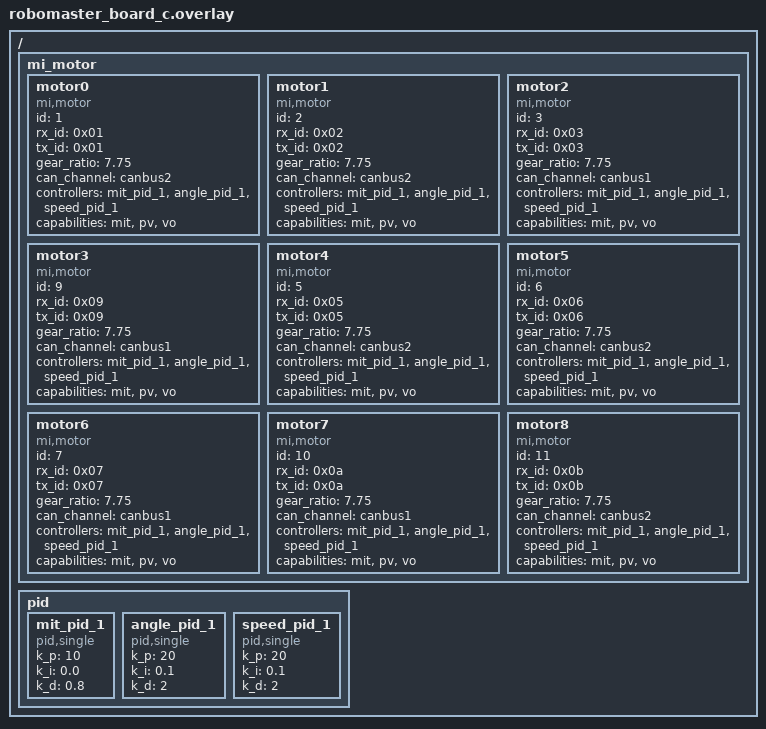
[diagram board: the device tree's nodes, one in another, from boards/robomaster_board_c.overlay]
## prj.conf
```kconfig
#启用线程分析器
# CONFIG_THREAD_ANALYZER=y
# CONFIG_THREAD_ANALYZER_USE_LOG=y
# CONFIG_THREAD_ANALYZER_USE_PRINTK=n
# CONFIG_THREAD_NAME=y
# CONFIG_THREAD_ANALYZER_AUTO=y
# CONFIG_THREAD_ANALYZER_AUTO_INTERVAL=5
# CONFIG_THREAD_ANALYZER_LOG_LEVEL_INF=y
# CONFIG_THREAD_ANALYZER_AUTO_SEPARATE_CORES=n

# 启用 UART 控制台
CONFIG_UART_CONSOLE=y

# 禁用 SEGGER RTT
CONFIG_USE_SEGGER_RTT=n

# 启用事件支持
CONFIG_EVENTS=y

# 启用串行支持
CONFIG_SERIAL=y
CONFIG_SPI_ASYNC=y
# 禁用优化
CONFIG_NO_OPTIMIZATIONS=y

# 启用驱动
CONFIG_MOTOR=y
# CONFIG_MOTOR_DJI=y
CONFIG_MOTOR_MI=y
CONFIG_MOTOR_LOG_LEVEL=4
CONFIG_CAN=y
CONFIG_MOTOR_INIT_PRIORITY=90
CONFIG_PID=y

CONFIG_ARES=y
CONFIG_ARES_SBUS=y
CONFIG_SBUS_INIT_PRIORITY=90

CONFIG_DMA=y
CONFIG_DMA_STM32=y  # STM32 DMA 驱动
CONFIG_UART_STM32=y # STM32 UART 驱动
# CONFIG_STM32_UART_DMA=y


# CONFIG_HAS_STM32CUBE=y
# CONFIG_USE_STM32_HAL_DMA=y
# CONFIG_SPI=y
# CONFIG_SPI_STM32=y

#
# Device Drivers
#
# CONFIG_SENSOR=y
# CONFIG_BMI08X=y
# CONFIG_BMI08X_ACCEL_TRIGGER_NONE is not set
# CONFIG_BMI08X_ACCEL_TRIGGER_GLOBAL_THREAD=y
# CONFIG_BMI08X_ACCEL_TRIGGER_OWN_THREAD is not set
# CONFIG_BMI08X_GYRO_TRIGGER_NONE is not set
# CONFIG_BMI08X_GYRO_TRIGGER_GLOBAL_THREAD=y
# CONFIG_BMI08X_GYRO_TRIGGER_OWN_THREAD is not set
# CONFIG_BMI08X_I2C_WRITE_BURST_SIZE=16

CONFIG_DEBUG_THREAD_INFO=y
CONFIG_MAIN_STACK_SIZE=4096
```

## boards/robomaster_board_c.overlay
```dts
/ {
	mi_motor {
		motor0: motor0{
			compatible = "mi,motor";
            
			id = <1>;
            rx_id = <0x01>;
            tx_id = <0x01>;
			gear_ratio = "7.75";
			status = "okay";
			can_channel = <&canbus2>;
			controllers = <&mit_pid_1 &angle_pid_1 &speed_pid_1>;
			capabilities = "mit","pv", "vo";
		};

		motor1: motor1{
			compatible = "mi,motor";
            
			id = <2>;
            rx_id = <0x02>;
            tx_id = <0x02>;
			gear_ratio = "7.75";
			status = "okay";
			can_channel = <&canbus2>;
			controllers = <&mit_pid_1 &angle_pid_1 &speed_pid_1>;
			capabilities = "mit","pv", "vo";
		};

		motor2: motor2{
			compatible = "mi,motor";
            
			id = <3>;
            rx_id = <0x03>;
            tx_id = <0x03>;
			gear_ratio = "7.75";
			status = "okay";
			can_channel = <&canbus1>;
			controllers = <&mit_pid_1 &angle_pid_1 &speed_pid_1>;
			capabilities = "mit","pv", "vo";
		};

		motor3: motor3{
			compatible = "mi,motor";
            
			id = <9>;
            rx_id = <0x09>;
            tx_id = <0x09>;
			gear_ratio = "7.75";
			status = "okay";
			can_channel = <&canbus1>;
			controllers = <&mit_pid_1 &angle_pid_1 &speed_pid_1>;
			capabilities = "mit","pv", "vo";
		};
		
		motor4: motor4{
			compatible = "mi,motor";
            
			id = <5>;
            rx_id = <0x05>;
            tx_id = <0x05>;
			gear_ratio = "7.75";
			status = "okay";
			can_channel = <&canbus2>;
			controllers = <&mit_pid_1 &angle_pid_1 &speed_pid_1>;
			capabilities = "mit","pv", "vo";
		};

		motor5: motor5{
			compatible = "mi,motor";
            
			id = <6>;
            rx_id = <0x06>;
            tx_id = <0x06>;
			gear_ratio = "7.75";
			status = "okay";
			can_channel = <&canbus2>;
			controllers = <&mit_pid_1 &angle_pid_1 &speed_pid_1>;
			capabilities = "mit","pv", "vo";
		};

		motor6: motor6{
			compatible = "mi,motor";
            
			id = <7>;
            rx_id = <0x07>;
            tx_id = <0x07>;
			gear_ratio = "7.75";
			status = "okay";
			can_channel = <&canbus1>;
			controllers = <&mit_pid_1 &angle_pid_1 &speed_pid_1>;
			capabilities = "mit","pv", "vo";
		};

		motor7: motor7{
			compatible = "mi,motor";
            
			id = <10>;
            rx_id = <0x0a>;
            tx_id = <0x0a>;
			gear_ratio = "7.75";
			status = "okay";
			can_channel = <&canbus1>;
			controllers = <&mit_pid_1 &angle_pid_1 &speed_pid_1>;
			capabilities = "mit","pv", "vo";
		};
		motor8: motor8{
			compatible = "mi,motor";
            
			id = <11>;
            rx_id = <0x0b>;
            tx_id = <0x0b>;
			gear_ratio = "7.75";
			status = "okay";
			can_channel = <&canbus2>;
			controllers = <&mit_pid_1 &angle_pid_1 &speed_pid_1>;
			capabilities = "mit","pv", "vo";
		};
	};

	pid {
		mit_pid_1: mit_pid_1 {
			#controller-cells = <0>;
			compatible = "pid,single";
			k_p = "10";
			k_i = "0.0";
			k_d = "0.8";
		};
		angle_pid_1: angle_pid_1 {
			#controller-cells = <0>;
			compatible = "pid,single";
			k_p = "20";
			k_i = "0.1";
			k_d = "2";
		};
		speed_pid_1: speed_pid_1 {
			#controller-cells = <0>;
			compatible = "pid,single";
			k_p = "20";
			k_i = "0.1";
			k_d = "2";
		};
		
	};
	
};
```

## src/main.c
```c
#include "ares/board/init.h"
#include "math.h"
#include <stddef.h>
#include <stdint.h>
#include <stdio.h>
#include <zephyr/debug/thread_analyzer.h>
#include <zephyr/device.h>
#include <zephyr/devicetree.h>
#include <zephyr/drivers/can.h>
#include <zephyr/drivers/motor.h>
#include <zephyr/drivers/sbus.h>
#include <zephyr/drivers/sensor.h>
#include <zephyr/drivers/uart.h>
#include <zephyr/kernel.h>
#include <zephyr/logging/log.h>
#include <zephyr/sys/printk.h>
#include "cycloid.h"

LOG_MODULE_REGISTER(main, LOG_LEVEL_DBG);

#define G 9.80665f

#define HIGH_BYTE(x) ((x) >> 8)
#define LOW_BYTE(x) ((x)&0xFF)
#define COMBINE_HL8(HIGH, LOW) ((HIGH << 8) + LOW)

#define MOTOR1_NODE DT_INST(0, mi_motor)
#define MOTOR2_NODE DT_INST(1, mi_motor)
#define MOTOR3_NODE DT_INST(2, mi_motor)
#define MOTOR4_NODE DT_INST(3, mi_motor)
#define MOTOR5_NODE DT_INST(4, mi_motor)
#define MOTOR6_NODE DT_INST(5, mi_motor)
#define MOTOR7_NODE DT_INST(6, mi_motor)
#define MOTOR8_NODE DT_INST(7, mi_motor)
#define MOTOR9_NODE DT_INST(8, mi_motor)

const struct device *motor1 = DEVICE_DT_GET(MOTOR1_NODE);
const struct device *motor2 = DEVICE_DT_GET(MOTOR2_NODE);
const struct device *motor3 = DEVICE_DT_GET(MOTOR3_NODE);
const struct device *motor4 = DEVICE_DT_GET(MOTOR4_NODE);
const struct device *motor5 = DEVICE_DT_GET(MOTOR5_NODE);
const struct device *motor6 = DEVICE_DT_GET(MOTOR6_NODE);
const struct device *motor7 = DEVICE_DT_GET(MOTOR7_NODE);
const struct device *motor8 = DEVICE_DT_GET(MOTOR8_NODE);
const struct device *motor9 = DEVICE_DT_GET(MOTOR8_NODE);

// #define TIMER_NODE DT_NODELABEL(timers10)
// const struct device *timer = DEVICE_DT_GET(TIMER_NODE);
k_tid_t feedback_tid = 0;
k_tid_t leg1_tid = 0;
k_tid_t leg2_tid = 0;
k_tid_t leg3_tid = 0;
k_tid_t leg4_tid = 0;
k_tid_t waist_tid = 0;

/* CAN Feedback to console*/
K_THREAD_STACK_DEFINE(feedback_stack_area, 4096); // 定义线程栈
void console_feedback(void *arg1, void *arg2, void *arg3) {

  while (1) {
    // LOG_INF("rpm: motor1: %.2f %.2f\n", (double)motor1_rpm,
    //         (double)motor_get_speed(motor1));
    // LOG_INF("rpm: motor2: %.2f %.2f\n", (double)motor2_rpm,
    //         (double)motor_get_speed(motor2));
    k_msleep(200);
  }
}

K_THREAD_STACK_DEFINE(leg1_stack, STACK_SIZE);
K_THREAD_STACK_DEFINE(leg2_stack, STACK_SIZE);
K_THREAD_STACK_DEFINE(leg3_stack, STACK_SIZE);
K_THREAD_STACK_DEFINE(leg4_stack, STACK_SIZE);
K_THREAD_STACK_DEFINE(waist_stack, STACK_SIZE);

float forward_angle1[TRAJ_POINTS];
float forward_angle4[TRAJ_POINTS];
float backward_angle1[TRAJ_POINTS];
float backward_angle4[TRAJ_POINTS];

int main(void) 
{
  Point2D start = {-0.15f, -0.20f};
  Point2D end = {0.15f, -0.2f};

  leg_motors leg1 = { motor1, motor2, LEFT_BACK};
  leg_motors leg2 = { motor4, motor3, RIGHT_BACK};
  leg_motors leg3 = { motor5, motor6, LEFT_FRONT};
  leg_motors leg4 = { motor8, motor7, RIGHT_FRONT};
  
  dog_initialization(start,end,forward_angle1,forward_angle4,backward_angle1,backward_angle4);
  k_sleep(K_MSEC(500)); 
  // motor_control(motor1, ENABLE_MOTOR); k_sleep(K_MSEC(10));
  // motor_control(motor2, ENABLE_MOTOR); k_sleep(K_MSEC(10));
  // motor_control(motor3, ENABLE_MOTOR); k_sleep(K_MSEC(10));
  // motor_control(motor4, ENABLE_MOTOR); k_sleep(K_MSEC(10));
  // motor_control(motor5, ENABLE_MOTOR); k_sleep(K_MSEC(10));
  // motor_control(motor6, ENABLE_MOTOR); k_sleep(K_MSEC(10));
  // motor_control(motor7, ENABLE_MOTOR); k_sleep(K_MSEC(10));
  // motor_control(motor8, ENABLE_MOTOR); k_sleep(K_MSEC(10));
  
  motor_set_mode(motor1, MIT);  k_sleep(K_MSEC(1));
  motor_set_mode(motor2, MIT);  k_sleep(K_MSEC(1));
  motor_set_mode(motor3, MIT);  k_sleep(K_MSEC(1));
  motor_set_mode(motor4, MIT);  k_sleep(K_MSEC(10));
  motor_set_mode(motor5, MIT);  k_sleep(K_MSEC(1));
  motor_set_mode(motor6, MIT);  k_sleep(K_MSEC(1));
  motor_set_mode(motor7, MIT);  k_sleep(K_MSEC(10));
  motor_set_mode(motor8, MIT);  k_sleep(K_MSEC(10));

  // Leg leg1 = { motor1, motor2, INITIAL_ANGLE1, INITIAL_ANGLE2, LEFT_BACK};
  // Leg leg2 = { motor4, motor3, INITIAL_ANGLE3, INITIAL_ANGLE4, RIGHT_BACK};
  // Leg leg3 = { motor5, motor6, INITIAL_ANGLE5, INITIAL_ANGLE6, LEFT_FRONT};
  // Leg leg4 = { motor8, motor7, INITIAL_ANGLE7, INITIAL_ANGLE8, RIGHT_FRONT};

  /* Start Feedback thread*/
  struct k_thread feedback_thread_data;
  struct k_thread leg1_thread_data;
  struct k_thread leg2_thread_data;
  struct k_thread leg3_thread_data;
  struct k_thread leg4_thread_data;
  struct k_thread waist_thread_data;

  k_sleep(K_MSEC(500));

  feedback_tid = k_thread_create(
      &feedback_thread_data,
      feedback_stack_area, // 修改为 can_send_stack_area
      K_THREAD_STACK_SIZEOF(feedback_stack_area), console_feedback,
      (void *)motor1, NULL, NULL, 0, 0, K_MSEC(300));

  leg1_tid = k_thread_create(&leg1_thread_data, leg1_stack, K_THREAD_STACK_SIZEOF(leg1_stack),
      leg_control_thread, &leg1, NULL, NULL,
      THREAD_PRIORITY, 0, K_NO_WAIT);

  leg2_tid = k_thread_create(&leg2_thread_data, leg2_stack, K_THREAD_STACK_SIZEOF(leg2_stack),
      leg_control_thread, &leg2, NULL, NULL,
      THREAD_PRIORITY, 0, K_NO_WAIT);

  leg3_tid = k_thread_create(&leg3_thread_data, leg3_stack, K_THREAD_STACK_SIZEOF(leg3_stack),
      leg_control_thread, &leg3, NULL, NULL,
      THREAD_PRIORITY, 0, K_NO_WAIT);

  leg4_tid = k_thread_create(&leg4_thread_data, leg4_stack, K_THREAD_STACK_SIZEOF(leg4_stack),
      leg_control_thread, &leg4, NULL, NULL,
      THREAD_PRIORITY, 0, K_NO_WAIT); 

  waist_tid = k_thread_create(&waist_thread_data, waist_stack, K_THREAD_STACK_SIZEOF(waist_stack),
      waist_control_thread, motor9, NULL, NULL,
      THREAD_PRIORITY, 0, K_NO_WAIT);

  k_sleep(K_MSEC(500));

  while (1) {  
  }
}
```

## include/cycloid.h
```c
#ifndef CYCLOID_H
#define CYCLOID_H

#include <stdint.h>
#include <zephyr/device.h>
#include <zephyr/kernel.h>
#include <zephyr/drivers/motor.h>
#include "math.h"

#define L1 0.09f
#define L2 0.224f
#define L3 0.224f
#define L4 0.09f
#define M_PI 3.14159265358979323846

#define CONTROL_CYCLE 10 // 控制周期10ms
#define TRAJ_POINTS 30   // 轨迹点数
#define BACK_TRAJ_POINTS 30
#define P_MOTOR  10
#define D_MOTOR  1
#define F_MOTOR  7
#define Torque 5

#define INITIAL_ANGLE1 45 //站定时刻对应电机角度
#define INITIAL_ANGLE2 -90
#define INITIAL_ANGLE3 90
#define INITIAL_ANGLE4 -45
#define INITIAL_ANGLE5 -45
#define INITIAL_ANGLE6 90
#define INITIAL_ANGLE7 -90
#define INITIAL_ANGLE8 45

#define TRAJ_INTERVAL 10

#define STACK_SIZE 4096
#define THREAD_PRIORITY -1

extern float g_target_theta1;
extern float g_target_theta4;

extern float forward_angle1[TRAJ_POINTS];
extern float forward_angle4[TRAJ_POINTS];
extern float backward_angle1[TRAJ_POINTS];
extern float backward_angle4[TRAJ_POINTS];

typedef enum
{
  GET_DOWN,
  STAND_UP,
  MOVE
}State;

typedef enum
{
  FORWARD,
  PAUSE_END,  // 终点停留
  BACKWARD,   // 返回起点
  PAUSE_START // 起点停留
}GaitState;

typedef enum
{
  LEFT_FRONT,
  RIGHT_FRONT,
  LEFT_BACK,
  RIGHT_BACK,
}legside;

typedef struct{
  const struct device *motor_a;
  const struct device *motor_b;
  const legside leg_side;
}leg_motors; 


typedef struct{
  const struct device *motor_a;
  const struct device *motor_b;
  const float initial_angle_a;
  const float initial_angle_b;
  const legside side;
  GaitState gait_state;
  // uint8_t leg_status;
  // uint32_t last_tick;
  // uint32_t start_time;
  uint8_t traj_index;
}Leg; 

typedef struct
{
  float x;
  float z;
}Point2D;

uint8_t inverse_kinematic(float x, float z, float *theta1, float *theta4);
void generate_cycloid(Point2D start, Point2D end, float height, Point2D *traj, int num_points);
void MotionControl(const struct device* motor, uint32_t total_time, uint8_t move, float start_angle, float target_angle, float speed);
void motor_control_thread(void* arg1 , void* arg2, void* arg3);
void leg_control_thread(void* arg1 , void* arg2, void* arg3);
void waist_control_thread(void* arg1 , void* arg2, void* arg3);
void dog_initialization(Point2D start, Point2D end, float *forward_theta1, float *forward_theta4, float *backward_theta1, float *backward_theta4);

#endif
```

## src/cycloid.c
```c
#include "cycloid.h"

float g_target_theta1 = 0;
float g_target_theta4 = 0;

/**  
 * @brief 插值运动控制
 * @param motor 电机设备
 * @param total_time 计划运行时间
 * @param move 计划运行步数
 * @param start_angle 初始角度
 * @param target_angle 目标角度
 */
void MotionControl(const struct device* motor, uint32_t total_time, uint8_t move, float start_angle, float target_angle, float speed)
{
  uint32_t each_time = total_time / move;
  float each_move = (target_angle - start_angle)/ move;
  for (int i = 0; i < move; i++)
  {
    // motor_set_torque(motor, Torque);
    motor_set_speed(motor, speed);
    motor_set_angle(motor, start_angle + each_move * (i + 1));
    k_msleep(each_time);
  }
}
/**
 *@brief 运动控制线程
 */
void motor_control_thread(void* arg1 , void* arg2, void* arg3)
{
  Leg *leg = (Leg *)arg1;
  ARG_UNUSED(arg2);
  ARG_UNUSED(arg3);

  extern State dog_state;
  while(1){
    switch(dog_state)
    {
      case GET_DOWN:
        break;
      case STAND_UP:
        break;
      case MOVE:
        break;
    }
  }
}
/**
 *@brief 站立控制线程
 */
void leg_control_thread(void* arg1 , void* arg2, void* arg3)
{

  leg_motors *leg = (leg_motors *)arg1;
  ARG_UNUSED(arg2);
  ARG_UNUSED(arg3);

  uint8_t init = 0;
  
  while(1){
    if (init == 0){   
      switch(leg->leg_side) {
        case LEFT_FRONT:
          MotionControl(leg->motor_a, 200, 5, 0, INITIAL_ANGLE5,1);
          MotionControl(leg->motor_b, 200, 5, 0, INITIAL_ANGLE6,1);
          k_msleep(TRAJ_INTERVAL);
          break;
          
        case RIGHT_FRONT:
          MotionControl(leg->motor_a, 200, 5, 0, INITIAL_ANGLE8,1);
          MotionControl(leg->motor_b, 200, 5, 0, INITIAL_ANGLE7,1);
          k_msleep(TRAJ_INTERVAL);
          break;

        case LEFT_BACK:
          MotionControl(leg->motor_a, 200, 5, 0, INITIAL_ANGLE1,1);
          MotionControl(leg->motor_b, 200, 5, 0, INITIAL_ANGLE2,1);
          k_msleep(TRAJ_INTERVAL);
          break;

        case RIGHT_BACK:
          MotionControl(leg->motor_a, 200, 5, 0, INITIAL_ANGLE4,1);
          MotionControl(leg->motor_b, 200, 5, 0, INITIAL_ANGLE3,1);
          k_msleep(TRAJ_INTERVAL);
          break;
      }
      init++;
    }
    else{
      for(int i = 0; i < TRAJ_POINTS; i++){
        switch(leg->leg_side){
          case LEFT_FRONT:
            // motor_set_torque(leg->motor_a, Torque);
            // motor_set_torque(leg->motor_b, Torque);
            motor_set_speed(leg->motor_a, 10);
            motor_set_speed(leg->motor_b, 10);
            motor_set_angle(leg->motor_a, INITIAL_ANGLE5 + forward_angle4[i]);
            motor_set_angle(leg->motor_b, INITIAL_ANGLE6 + forward_angle1[i]);
            k_msleep(TRAJ_INTERVAL);
            break;
          case LEFT_BACK:
            // motor_set_torque(leg->motor_a, Torque);
            // motor_set_torque(leg->motor_b, Torque);
            motor_set_speed(leg->motor_a, 10);
            motor_set_speed(leg->motor_b, 10);
            motor_set_angle(leg->motor_a, INITIAL_ANGLE1 - backward_angle1[i]);
            motor_set_angle(leg->motor_b, INITIAL_ANGLE2 - backward_angle4[i]);
            k_msleep(TRAJ_INTERVAL);
            break;
          case RIGHT_FRONT:
            // motor_set_torque(leg->motor_a, Torque);
            // motor_set_torque(leg->motor_b, Torque);
            motor_set_speed(leg->motor_a, 10);
            motor_set_speed(leg->motor_b, 10);
            motor_set_angle(leg->motor_a, INITIAL_ANGLE8 - backward_angle4[i]);
            motor_set_angle(leg->motor_b, INITIAL_ANGLE7 - backward_angle1[i]);
            k_msleep(TRAJ_INTERVAL);
            break;
          case RIGHT_BACK:
            // motor_set_torque(leg->motor_a, Torque);
            // motor_set_torque(leg->motor_b, Torque);
            motor_set_speed(leg->motor_a, 10);
            motor_set_speed(leg->motor_b, 10);
            motor_set_angle(leg->motor_a, INITIAL_ANGLE4 + forward_angle1[i]);
            motor_set_angle(leg->motor_b, INITIAL_ANGLE3 + forward_angle4[i]);
            k_msleep(TRAJ_INTERVAL);
            break;
        }
      }
      for(int i = 0; i < BACK_TRAJ_POINTS; i++){
        switch(leg->leg_side){
          case LEFT_BACK:
            // motor_set_torque(leg->motor_a, Torque);
            // motor_set_torque(leg->motor_b, Torque);
            motor_set_speed(leg->motor_a, 10);
            motor_set_speed(leg->motor_b, 10);
            motor_set_angle(leg->motor_a, INITIAL_ANGLE1 - forward_angle1[i]);
            motor_set_angle(leg->motor_b, INITIAL_ANGLE2 - forward_angle4[i]);
            k_msleep(TRAJ_INTERVAL);
            break;
          case LEFT_FRONT:
            // motor_set_torque(leg->motor_a, Torque);
            // motor_set_torque(leg->motor_b, Torque);
            motor_set_speed(leg->motor_a, 10);
            motor_set_speed(leg->motor_b, 10);
            motor_set_angle(leg->motor_a, INITIAL_ANGLE5 + backward_angle4[i]);
            motor_set_angle(leg->motor_b, INITIAL_ANGLE6 + backward_angle1[i]);
            k_msleep(TRAJ_INTERVAL);
            break;
          case RIGHT_BACK:
            // motor_set_torque(leg->motor_a, Torque);
            // motor_set_torque(leg->motor_b, Torque);
            motor_set_speed(leg->motor_a, 10);
            motor_set_speed(leg->motor_b, 10);
            motor_set_angle(leg->motor_a, INITIAL_ANGLE4 + backward_angle1[i]);
            motor_set_angle(leg->motor_b, INITIAL_ANGLE3 + backward_angle4[i]);
            k_msleep(TRAJ_INTERVAL);
            break;
          case RIGHT_FRONT:
            // motor_set_torque(leg->motor_a, Torque);
            // motor_set_torque(leg->motor_b, Torque);
            motor_set_speed(leg->motor_a, 10);
            motor_set_speed(leg->motor_b, 10);
            motor_set_angle(leg->motor_a, INITIAL_ANGLE8 - forward_angle4[i]);
            motor_set_angle(leg->motor_b, INITIAL_ANGLE7 - forward_angle1[i]);
            k_msleep(TRAJ_INTERVAL);
            break;
        }
      }
    }  
  }  
}
/**
 * @brief 腰部控制线程
 */
void waist_control_thread(void* arg1 , void* arg2, void* arg3){
  const struct device *motor = (const struct device *)arg1;
  ARG_UNUSED(arg2);
  ARG_UNUSED(arg3);
  
  uint8_t init = 0;
  while(1){
    if(init == 0){
      k_msleep(200);
      MotionControl(motor, 500, 20, 0, -45, 1);
      k_msleep(TRAJ_INTERVAL);
      init++;
    }
    else{
      MotionControl(motor, 1000, 40, -45, 45, 1);
      k_msleep(TRAJ_INTERVAL);
      MotionControl(motor, 1000, 40, 45, -45, 1);
      k_msleep(TRAJ_INTERVAL);
    }
  }
}
/**  
 * @brief 逆运动学解算
 * @param x: x坐标
 * @param z: z坐标
 * @param theta1: 电机1角度
 * @param theta4: 电机4角度
 * @return 0: 表示解算失败
 * @return 1: 表示解算成功
 */
uint8_t inverse_kinematic(float x, float z, float *theta1, float *theta4)
{
  float l0 = sqrtf(x * x + z * z);

  if (fabsf(L3 - L4) >= l0 || l0 >= (L3 + L4))
  {
    return 0; // 返回错误标志
  }

  float theta_inside = acosf((L4 * L4 + l0 * l0 - L3 * L3) / (2 * L4 * l0));
  float theta = atan2f(z, x);

  *theta1 = theta + theta_inside;
  *theta4 = theta - theta_inside;
  return 1; // 成功标志
}

/**
 * @brief 生成摆线轨迹
 * @param start: 起点
 * @param end: 终点
 * @param height: 高度
 * @param traj: 轨迹
 * @param num_points: 轨迹点数
 */
void generate_cycloid(Point2D start, Point2D end, float height, Point2D *traj, int num_points)
{
  float delta_x = end.x - start.x;
  float delta_z = end.z - start.z; // 起点与落点可能存在高度差

  for (int i = 0; i < num_points; ++i)
  {
    float t = 2 * M_PI * i / (num_points - 1);

    // X方向摆线
    traj[i].x = start.x + delta_x * (t - sinf(t)) / (2 * M_PI);

    traj[i].z = start.z + delta_z * (i / (float)num_points) + height * (1 - cosf(t)) / 2; // 关键修改：height取反
  }
}
/**
*@brief 初始化步态
*@param start 目标电位起始点
*@param end 目标电位终止点
*@param forward_theta1 电机1去程角度
*@param forward_theta4 电机4去程角度
*@param backward_theta1 电机1回程角度
*@param backward_theta4 电机4回程角度
**/
void dog_initialization(Point2D start, Point2D end, float *forward_theta1, float *forward_theta4, float *backward_theta1, float *backward_theta4)
{
  Point2D forward_trajectory[TRAJ_POINTS];
  Point2D backward_trajectory[BACK_TRAJ_POINTS];
  generate_cycloid(start, end, 0.04f, forward_trajectory, TRAJ_POINTS);
  generate_cycloid(end, start, -0.04f, backward_trajectory, BACK_TRAJ_POINTS);

  for (int i = 0; i < TRAJ_POINTS; i++)
  {
    Point2D current = forward_trajectory[i];
    float theta1, theta4;
    if(inverse_kinematic(current.x, current.z, &theta1, &theta4))
    {
      forward_theta1[i] = -theta1 * 180/M_PI;
      forward_theta4[i] = (theta4 + M_PI) * 180/M_PI;
    }
  }
  for(int i = 0; i < BACK_TRAJ_POINTS; i++)
  {
    Point2D current = backward_trajectory[i];
    float theta1, theta4;
    if(inverse_kinematic(current.x, current.z, &theta1, &theta4))
    {
      backward_theta1[i] = -theta1 * 180/M_PI;;
      backward_theta4[i] = (theta4 + M_PI) * 180/M_PI;
    }
  }
  k_msleep(1000);
}
```
